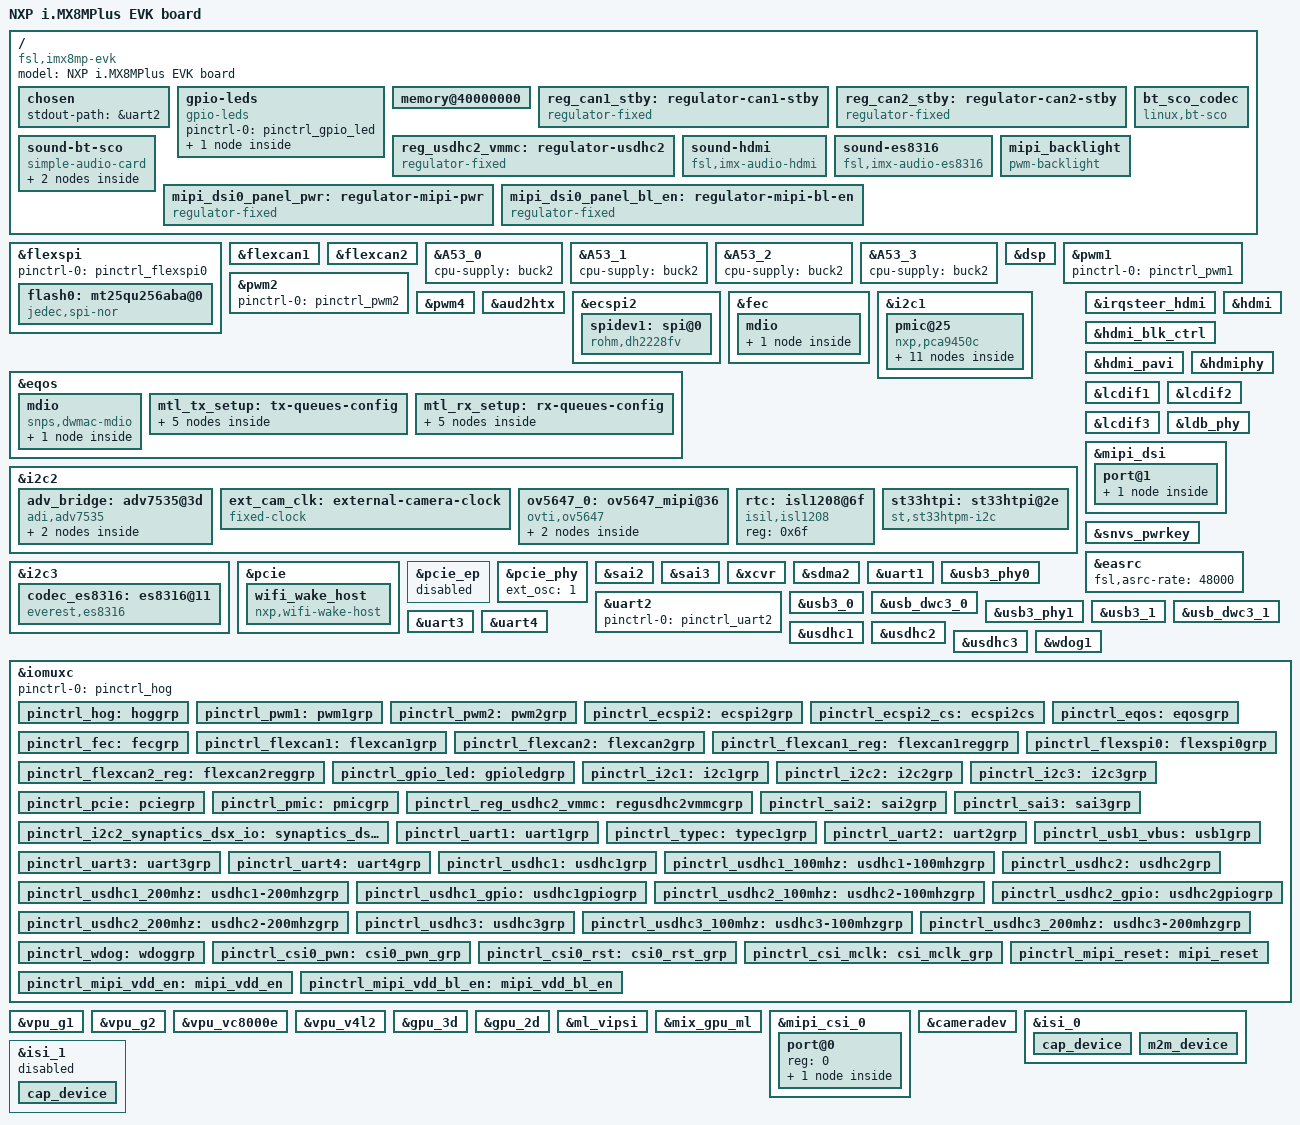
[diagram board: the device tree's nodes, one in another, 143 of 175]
// SPDX-License-Identifier: (GPL-2.0+ OR MIT)
/*
 * Copyright 2019 NXP
 */

/dts-v1/;

#include <dt-bindings/usb/pd.h>
#include "imx8mp.dtsi"

/ {
	model = "NXP i.MX8MPlus EVK board";
	compatible = "fsl,imx8mp-evk", "fsl,imx8mp";

	chosen {
		stdout-path = &uart2;
	};

	gpio-leds {
		compatible = "gpio-leds";
		pinctrl-names = "default";
		pinctrl-0 = <&pinctrl_gpio_led>;

		status {
			label = "yellow:status";
			gpios = <&gpio3 16 GPIO_ACTIVE_HIGH>;
			default-state = "on";
		};
	};

	memory@40000000 {
		device_type = "memory";
		reg = <0x0 0x40000000 0 0xc0000000>,
		      <0x1 0x00000000 0 0xc0000000>;
	};

	// mickey canbus test
	reg_can1_stby: regulator-can1-stby {
		compatible = "regulator-fixed";
		regulator-name = "can1-stby";
		pinctrl-names = "default";
		pinctrl-0 = <&pinctrl_flexcan1_reg>;
		regulator-min-microvolt = <3300000>;
		regulator-max-microvolt = <3300000>;
		gpio = <&gpio5 5 GPIO_ACTIVE_LOW>;
	};

	reg_can2_stby: regulator-can2-stby {
		compatible = "regulator-fixed";
		regulator-name = "can2-stby";
		pinctrl-names = "default";
		pinctrl-0 = <&pinctrl_flexcan2_reg>;
		regulator-min-microvolt = <3300000>;
		regulator-max-microvolt = <3300000>;
		gpio = <&gpio4 27 GPIO_ACTIVE_LOW>;
	};

	/* mickey org code
	reg_can1_stby: regulator-can1-stby {
		compatible = "regulator-fixed";
		regulator-name = "can1-stby";
		pinctrl-names = "default";
		pinctrl-0 = <&pinctrl_flexcan1_reg>;
		regulator-min-microvolt = <3300000>;
		regulator-max-microvolt = <3300000>;
		gpio = <&gpio5 5 GPIO_ACTIVE_HIGH>;
		enable-active-high;
	};

	reg_can2_stby: regulator-can2-stby {
		compatible = "regulator-fixed";
		regulator-name = "can2-stby";
		pinctrl-names = "default";
		pinctrl-0 = <&pinctrl_flexcan2_reg>;
		regulator-min-microvolt = <3300000>;
		regulator-max-microvolt = <3300000>;
		gpio = <&gpio4 27 GPIO_ACTIVE_HIGH>;
		enable-active-high;
	};
	*/
	
	// mickey, mmc0, remark by h/w design
	/*
	reg_usdhc1_vmmc: regulator-usdhc1 {
		compatible = "regulator-fixed";
		pinctrl-names = "default";
		//pinctrl-0 = <&pinctrl_reg_usdhc1_vmmc>;
		regulator-name = "VSD1_3V3";
		regulator-min-microvolt = <3300000>;
		regulator-max-microvolt = <3300000>;
		//gpio = <&gpio2 10 GPIO_ACTIVE_HIGH>;
		//enable-active-high;
	};
	*/
	
	reg_usdhc2_vmmc: regulator-usdhc2 {
		compatible = "regulator-fixed";
		pinctrl-names = "default";
		pinctrl-0 = <&pinctrl_reg_usdhc2_vmmc>;
		regulator-name = "VSD_3V3";
		regulator-min-microvolt = <3300000>;
		regulator-max-microvolt = <3300000>;
		gpio = <&gpio2 19 GPIO_ACTIVE_HIGH>;
		enable-active-high;
	};

	/* es8316 no need, so remark
	reg_audio_pwr: regulator-audio-pwr {
		compatible = "regulator-fixed";
		regulator-name = "audio-pwr";
		regulator-min-microvolt = <3300000>;
		regulator-max-microvolt = <3300000>;
		gpio = <&gpio4 29 GPIO_ACTIVE_HIGH>;
		enable-active-high;
		regulator-always-on;
	};
	*/

	bt_sco_codec: bt_sco_codec {
		#sound-dai-cells = <1>;
		compatible = "linux,bt-sco";
	};

	sound-bt-sco {
		compatible = "simple-audio-card";
		simple-audio-card,name = "bt-sco-audio";
		simple-audio-card,format = "dsp_a";
		simple-audio-card,bitclock-inversion;
		simple-audio-card,frame-master = <&btcpu>;
		simple-audio-card,bitclock-master = <&btcpu>;

		btcpu: simple-audio-card,cpu {
			sound-dai = <&sai2>;
			dai-tdm-slot-num = <2>;
			dai-tdm-slot-width = <16>;
		};

		/* mickey, org code */
		/*
		simple-audio-card,codec {
			sound-dai = <&bt_sco_codec 1>;
		};
		*/

		/* mickey */
		simple-audio-card,codec_es8316 {
			sound-dai = <&bt_sco_codec 1>;
		};
	};

	sound-hdmi {
		compatible = "fsl,imx-audio-hdmi";
		model = "audio-hdmi";
		audio-cpu = <&aud2htx>;
		hdmi-out;
		constraint-rate = <44100>,
				<88200>,
				<176400>,
				<32000>,
				<48000>,
				<96000>,
				<192000>;
		status = "okay";
	};

	/* mickey, org audio codec.
	sound-wm8960 {
		compatible = "fsl,imx-audio-wm8960";
		model = "wm8960-audio";
		audio-cpu = <&sai3>;
		audio-codec = <&codec>;
		audio-asrc = <&easrc>;
		hp-det-gpio = <&gpio4 28 0>;
		audio-routing =
			"Headphone Jack", "HP_L",
			"Headphone Jack", "HP_R",
			"Ext Spk", "SPK_LP",
			"Ext Spk", "SPK_LN",
			"Ext Spk", "SPK_RP",
			"Ext Spk", "SPK_RN",
			"LINPUT1", "Mic Jack",
			"LINPUT3", "Mic Jack",
			"Mic Jack", "MICB";
	};
	*/

	/* mickey, es8316 codec, audio-codec = <&codec>; */
    	sound-es8316 {
		compatible = "fsl,imx-audio-es8316";
		model = "imx-audio-es8316";
		audio-cpu = <&sai3>;
		audio-codec = <&codec_es8316>;
		//hp-det-gpio = <&gpio4 28 0>;
		simple-audio-card,format = "i2s";
		simple-audio-card,mclk-fs = <256>;
		simple-audio-card,widgets =
			"Microphone", "Mic Jack",
			"Headphone", "Headphone Jack";
		simple-audio-card,routing =
			"Mic Jack", "MICBIAS1",
			"IN1P", "Mic Jack",
		    	"Headphone Jack", "HPOL",
		    	"Headphone Jack", "HPOR";
		audio-routing = 
		    	"Headphone Jack", "HPOL",
		    	"Headphone Jack", "HPOR";
    	};

	/* mickey, remark due to not using
	sound-micfil {
		compatible = "fsl,imx-audio-card";
		model = "imx-audio-micfil";
		pri-dai-link {
			link-name = "micfil hifi";
			format = "i2s";
			cpu {
				sound-dai = <&micfil>;
			};
		};
	};
	*/

	/* mickey, remark due to not using
	sound-xcvr {
		compatible = "fsl,imx-audio-card";
		model = "imx-audio-xcvr";
		pri-dai-link {
			link-name = "XCVR PCM";
			cpu {
				sound-dai = <&xcvr>;
			};
		};
	};
	*/
	
	// mickey, auo lvds 21 inch, vdd en
	/* default using HDMI, so remark lvds
	lvds0_panel_pwr: regulator-lvds-pwr {
	    	compatible = "regulator-fixed";
    		regulator-name = "lvds-pwr";
    		pinctrl-0 = <&pinctrl_lvds_vdd_en>;
    		gpio = <&gpio1 10 GPIO_ACTIVE_HIGH>;
    		enable-active-high;
		regulator-boot-on;
		regulator-always-on;
	};
	
	// mickey, auo lvds 21 inch, bl en
	lvds0_panel_bl_en: regulator-lvds-bl-en {
	    	compatible = "regulator-fixed";
    		regulator-name = "lvds-bl-en";
    		pinctrl-0 = <&pinctrl_lvds_vdd_bl_en>;
    		gpio = <&gpio1 13 GPIO_ACTIVE_HIGH>;
    		enable-active-high;
		regulator-boot-on;
		regulator-always-on;
	};
	
	// mickey, auo lvds 21 inch
	lvds0_panel {
		compatible = "auo,t215hvn01";
		//compatible = "auo,m215htn01";
		regulator-name = "panel-simple";
		power-supply = <&lvds0_panel_pwr>;
		backlight = <&lvds_backlight>;
		
		data-mapping = "24";
		width-mm = <430>;
		height-mm = <270>;
		
		panel-timing {
			//clock-frequency = <72000000>; // typical value of 71.2 MHz
			clock-frequency = <148800000>;
			hactive = <1920>;
			vactive = <1080>;
			hsync-len = <44>;
			hback-porch = <88>;
			hfront-porch = <148>;
			vsync-len = <5>;
			vback-porch = <4>;
			vfront-porch = <36>;
			hsync-active = <0>;
			vsync-active = <0>;
		};

		port {
			panel_lvds0_in: endpoint {
				remote-endpoint = <&lvds0_out>;
			};
		};
	};

	lvds_backlight: lvds_backlight {
		compatible = "pwm-backlight";
		pwms = <&pwm2 0 100000>;
		status = "okay";
		power-supply = <&lvds0_panel_bl_en>;

		brightness-levels = < 0  1  2  3  4  5  6  7  8  9
				     10 11 12 13 14 15 16 17 18 19
				     20 21 22 23 24 25 26 27 28 29
				     30 31 32 33 34 35 36 37 38 39
				     40 41 42 43 44 45 46 47 48 49
				     50 51 52 53 54 55 56 57 58 59
				     60 61 62 63 64 65 66 67 68 69
				     70 71 72 73 74 75 76 77 78 79
				     80 81 82 83 84 85 86 87 88 89
				     90 91 92 93 94 95 96 97 98 99
				    100>;
		default-brightness-level = <80>;
	};
	*/

	/* mickey, remark due to not using
	cbtl04gp {
		compatible = "nxp,cbtl04gp";
		pinctrl-names = "default";
		pinctrl-0 = <&pinctrl_typec_mux>;
		switch-gpios = <&gpio4 20 GPIO_ACTIVE_LOW>;
		orientation-switch;

		port {
			usb3_data_ss: endpoint {
				remote-endpoint = <&typec_con_ss>;
			};
		};
	};
	*/
	
	// mickey, mipi dsi vcc en, gpio1 10
	mipi_dsi0_panel_pwr: regulator-mipi-pwr {
	    	compatible = "regulator-fixed";
    		regulator-name = "mipi-pwr";
    		pinctrl-0 = <&pinctrl_mipi_vdd_en>;
    		gpio = <&gpio1 10 GPIO_ACTIVE_HIGH>;
    		enable-active-high;
		//regulator-boot-on;
		//regulator-always-on;
	};
	
	// mickey, mipi dsi bl en, gpio1 9
	mipi_dsi0_panel_bl_en: regulator-mipi-bl-en {
	    	compatible = "regulator-fixed";
    		regulator-name = "mipi-bl-en";
    		pinctrl-0 = <&pinctrl_mipi_vdd_bl_en>;
    		gpio = <&gpio1 9 GPIO_ACTIVE_HIGH>;
    		enable-active-high;
		//regulator-boot-on;
		//regulator-always-on;
	};
	
	// mickey, mipi backlight
	mipi_backlight: mipi_backlight {
		compatible = "pwm-backlight";
		pwms = <&pwm1 0 100000>;
		power-supply = <&mipi_dsi0_panel_bl_en>;
		brightness-levels = < 
			0  1  2  3  4  5  6  7  8  9
			10 11 12 13 14 15 16 17 18 19
			20 21 22 23 24 25 26 27 28 29
			30 31 32 33 34 35 36 37 38 39
			40 41 42 43 44 45 46 47 48 49
			50 51 52 53 54 55 56 57 58 59
			60 61 62 63 64 65 66 67 68 69
			70 71 72 73 74 75 76 77 78 79
			80 81 82 83 84 85 86 87 88 89
			90 91 92 93 94 95 96 97 98 99
			100
		>;
		default-brightness-level = <100>;	
		status = "okay";
	};	
};

&flexspi {
	pinctrl-names = "default";
	pinctrl-0 = <&pinctrl_flexspi0>;
	status = "okay";

	flash0: mt25qu256aba@0 {
		reg = <0>;
		#address-cells = <1>;
		#size-cells = <1>;
		compatible = "jedec,spi-nor";
		spi-max-frequency = <80000000>;
		spi-tx-bus-width = <1>;
		spi-rx-bus-width = <4>;
	};
};

&flexcan1 {
	pinctrl-names = "default";
	pinctrl-0 = <&pinctrl_flexcan1>;
	xceiver-supply = <&reg_can1_stby>;
	status = "okay";
};

// mickey, remove pca6416, due to have no h/w s/w btn.
&flexcan2 {
	pinctrl-names = "default";
	pinctrl-0 = <&pinctrl_flexcan2>;
	xceiver-supply = <&reg_can2_stby>;
	//pinctrl-assert-gpios = <&pca6416 3 GPIO_ACTIVE_HIGH>;
	status = "okay";/* can2 pin conflict with pdm */
};

&A53_0 {
	cpu-supply = <&buck2>;
};

&A53_1 {
	cpu-supply = <&buck2>;
};

&A53_2 {
	cpu-supply = <&buck2>;
};

&A53_3 {
	cpu-supply = <&buck2>;
};

&dsp {
	status = "okay";
};

&pwm1 {
	pinctrl-names = "default";
	pinctrl-0 = <&pinctrl_pwm1>;
	status = "okay";
};

&pwm2 {
	pinctrl-names = "default";
	
	pinctrl-0 = <&pinctrl_pwm2>;
	status = "okay";
};

&pwm4 {
	pinctrl-names = "default";
	//pinctrl-0 = <&pinctrl_pwm4>; // mickey, remove
	status = "okay";
};

&aud2htx {
	status = "okay";
};

&ecspi2 {
	#address-cells = <1>;
	#size-cells = <0>;
	fsl,spi-num-chipselects = <1>;
	pinctrl-names = "default";
	pinctrl-0 = <&pinctrl_ecspi2 &pinctrl_ecspi2_cs>;
	cs-gpios = <&gpio5 13 GPIO_ACTIVE_LOW>;
	status = "okay";

	spidev1: spi@0 {
		reg = <0>;
		compatible = "rohm,dh2228fv";
		spi-max-frequency = <500000>;
	};
};

// mickey test 1G issue
&eqos {
	pinctrl-names = "default";
	pinctrl-0 = <&pinctrl_eqos>;
	phy-mode = "rgmii-id";
	phy-handle = <&ethphy0>;
	snps,force_thresh_dma_mode;
	snps,mtl-tx-config = <&mtl_tx_setup>;
	snps,mtl-rx-config = <&mtl_rx_setup>;
	status = "okay";

	// mickey test 1G
	/*
	fixed-link {
		speed = <1000>;
		full-duplex;
		pause;
	};
	*/

	mdio {
		compatible = "snps,dwmac-mdio";
		#address-cells = <1>;
		#size-cells = <0>;

		ethphy0: ethernet-phy@2 {
			compatible = "ethernet-phy-ieee802.3-c22";
			//compatible = "micrel,ksz9031";
			rxc-skew-ps = <1800>;
			rxdv-skew-ps = <0>;
			txc-skew-ps = <1800>;
			txen-skew-ps = <0>;
			reg = <2>;
			adi,rx-internal-delay-ps = <1800>; // mickey, test adin
		        adi,tx-internal-delay-ps = <2200>; // mickey, test adin
		        adi,fifo-depth-bits = <16>; // mickey, test adin
			eee-broken-1000t;
		};
	};

	mtl_tx_setup: tx-queues-config {
		snps,tx-queues-to-use = <5>;
		snps,tx-sched-sp;
		queue0 {
			snps,dcb-algorithm;
			snps,priority = <0x1>;
		};
		queue1 {
			snps,dcb-algorithm;
			snps,priority = <0x2>;
		};
		queue2 {
			snps,dcb-algorithm;
			snps,priority = <0x4>;
		};
		queue3 {
			snps,dcb-algorithm;
			snps,priority = <0x8>;
		};
		queue4 {
			snps,dcb-algorithm;
			snps,priority = <0xf0>;
		};
	};
	mtl_rx_setup: rx-queues-config {
		snps,rx-queues-to-use = <5>;
		snps,rx-sched-sp;
		queue0 {
			snps,dcb-algorithm;
			snps,priority = <0x1>;
			snps,map-to-dma-channel = <0>;
		};
		queue1 {
			snps,dcb-algorithm;
			snps,priority = <0x2>;
			snps,map-to-dma-channel = <1>;
		};
		queue2 {
			snps,dcb-algorithm;
			snps,priority = <0x4>;
			snps,map-to-dma-channel = <2>;
		};
		queue3 {
			snps,dcb-algorithm;
			snps,priority = <0x8>;
			snps,map-to-dma-channel = <3>;
		};
		queue4 {
			snps,dcb-algorithm;
			snps,priority = <0xf0>;
			snps,map-to-dma-channel = <4>;
		};
	};
};

&fec {
	pinctrl-names = "default";
	pinctrl-0 = <&pinctrl_fec>;
	phy-mode = "rgmii-id";
	phy-handle = <&ethphy1>;
	fsl,magic-packet;
	status = "okay";
	
	// mickey test 1G
	/*
	fixed-link {
		speed = <1000>;
		full-duplex;
		pause;
	};
	*/

	mdio {
		#address-cells = <1>;
		#size-cells = <0>;

		ethphy1: ethernet-phy@1 {
			compatible = "ethernet-phy-ieee802.3-c22";
			//compatible = "micrel,ksz9031";
			rxc-skew-ps = <1800>;
			rxdv-skew-ps = <0>;
			txc-skew-ps = <1800>;
			txen-skew-ps = <0>;
			reg = <1>;
			adi,rx-internal-delay-ps = <1800>; // mickey, test adin
		        adi,tx-internal-delay-ps = <2200>; // mickey, test adin
		        adi,fifo-depth-bits = <16>; // mickey, test adin
			eee-broken-1000t;
			// lan1 reset pin, gpio98
			//reset-gpios = <&gpio4 2 GPIO_ACTIVE_LOW>;
			reset-assert-us = <10000>;
			reset-deassert-us = <80000>;
		};
	};
};
// mickey test 1G issue

/* org code
&fec {
	pinctrl-names = "default";
	pinctrl-0 = <&pinctrl_fec>;
	phy-mode = "rgmii-id";
	phy-handle = <&ethphy1>;
	fsl,magic-packet;
	status = "okay";

	mdio {
		#address-cells = <1>;
		#size-cells = <0>;

		ethphy1: ethernet-phy@0 {
			compatible = "ethernet-phy-ieee802.3-c22";
			reg = <0>;
			reset-assert-us = <10000>;
			reset-deassert-us = <80000>;
		};
	};
};
*/

&i2c1 {
	clock-frequency = <400000>;
	pinctrl-names = "default";
	pinctrl-0 = <&pinctrl_i2c1>;
	status = "okay";

	pmic@25 {
		compatible = "nxp,pca9450c";
		reg = <0x25>;
		pinctrl-names = "default";
		pinctrl-0 = <&pinctrl_pmic>;
		interrupt-parent = <&gpio1>;
		interrupts = <3 IRQ_TYPE_LEVEL_LOW>;

		regulators {
			buck1: BUCK1 {
				regulator-name = "BUCK1";
				regulator-min-microvolt = <600000>;
				regulator-max-microvolt = <2187500>;
				regulator-boot-on;
				regulator-always-on;
				regulator-ramp-delay = <3125>;
			};

			buck2: BUCK2 {
				regulator-name = "BUCK2";
				regulator-min-microvolt = <600000>;
				regulator-max-microvolt = <2187500>;
				regulator-boot-on;
				regulator-always-on;
				regulator-ramp-delay = <3125>;
				nxp,dvs-run-voltage = <950000>;
				nxp,dvs-standby-voltage = <850000>;
			};

			buck4: BUCK4{
				regulator-name = "BUCK4";
				regulator-min-microvolt = <600000>;
				regulator-max-microvolt = <3400000>;
				regulator-boot-on;
				regulator-always-on;
			};

			buck5: BUCK5{
				regulator-name = "BUCK5";
				regulator-min-microvolt = <600000>;
				regulator-max-microvolt = <3400000>;
				regulator-boot-on;
				regulator-always-on;
			};

			buck6: BUCK6 {
				regulator-name = "BUCK6";
				regulator-min-microvolt = <600000>;
				regulator-max-microvolt = <3400000>;
				regulator-boot-on;
				regulator-always-on;
			};

			ldo1: LDO1 {
				regulator-name = "LDO1";
				regulator-min-microvolt = <1600000>;
				regulator-max-microvolt = <3300000>;
				regulator-boot-on;
				regulator-always-on;
			};

			ldo2: LDO2 {
				regulator-name = "LDO2";
				regulator-min-microvolt = <800000>;
				regulator-max-microvolt = <1150000>;
				regulator-boot-on;
				regulator-always-on;
			};

			ldo3: LDO3 {
				regulator-name = "LDO3";
				regulator-min-microvolt = <800000>;
				regulator-max-microvolt = <3300000>;
				regulator-boot-on;
				regulator-always-on;
			};

			ldo4: LDO4 {
				regulator-name = "LDO4";
				regulator-min-microvolt = <800000>;
				regulator-max-microvolt = <3300000>;
				regulator-boot-on;
				regulator-always-on;
			};

			ldo5: LDO5 {
				regulator-name = "LDO5";
				regulator-min-microvolt = <1800000>;
				regulator-max-microvolt = <3300000>;
				regulator-boot-on;
				regulator-always-on;
			};
		};
	};
};

&i2c2 {
	clock-frequency = <100000>;
	pinctrl-names = "default";
	pinctrl-0 = <&pinctrl_i2c2>;
	status = "okay";

	/* mickey, remove, due to not use */
	adv_bridge: adv7535@3d {
		compatible = "adi,adv7535";
		reg = <0x3d>;
		adi,addr-cec = <0x3b>;
		adi,dsi-lanes = <4>;
		status = "okay";

		port {
			adv7535_from_dsim: endpoint {
				remote-endpoint = <&dsim_to_adv7535>;
			};
		};
	};

	/* mickey, remove, due to not use
	lvds_bridge: lvds-to-hdmi-bridge@4c {
		compatible = "ite,it6263";
		reg = <0x4c>;
		reset-gpios = <&gpio1 10 GPIO_ACTIVE_LOW>;

		port {
			it6263_in: endpoint {
				remote-endpoint = <&lvds_out>;
			};
		};
	};
	*/

	/* org code
	ov5640_0: ov5640_mipi@3c {
		compatible = "ovti,ov5640";
		reg = <0x3c>;
		pinctrl-names = "default";
		pinctrl-0 = <&pinctrl_csi0_pwn>, <&pinctrl_csi0_rst>, <&pinctrl_csi_mclk>;
		clocks = <&clk IMX8MP_CLK_IPP_DO_CLKO2>;
		clock-names = "xclk";
		assigned-clocks = <&clk IMX8MP_CLK_IPP_DO_CLKO2>;
		assigned-clock-parents = <&clk IMX8MP_CLK_24M>;
		assigned-clock-rates = <24000000>;
		csi_id = <0>;
		powerdown-gpios = <&gpio2 11 GPIO_ACTIVE_HIGH>;
		reset-gpios = <&gpio1 6 GPIO_ACTIVE_LOW>;
		mclk = <24000000>;
		mclk_source = <0>;
		mipi_csi;
		status = "okay";

		port {
			ov5640_mipi_0_ep: endpoint {
				remote-endpoint = <&mipi_csi0_ep>;
				data-lanes = <1 2>;
				clock-lanes = <0>;
			};
		};
	};
	*/
	
	// mickey, test for ov5647
	ext_cam_clk: external-camera-clock {
	        compatible = "fixed-clock";
       	clock-frequency = <25000000>;
       	clock-output-names = "CLK_CAMERA_25MHZ";
       	#clock-cells = <0>;
    	}; 
	
	ov5647_0: ov5647_mipi@36 {
		compatible = "ovti,ov5647";
		reg = <0x36>;
		pinctrl-names = "default";
		pinctrl-0 = <&pinctrl_csi0_pwn>, <&pinctrl_csi0_rst>, <&pinctrl_csi_mclk>;
		clocks = <&ext_cam_clk>; 
		//clocks = <&clk IMX8MP_CLK_IPP_DO_CLKO2>;
		//clock-names = "xclk";
		//assigned-clocks = <&clk IMX8MP_CLK_IPP_DO_CLKO2>;
		//assigned-clock-parents = <&clk IMX8MP_CLK_24M>;
		//assigned-clock-rates = <24000000>;
		csi_id = <0>;
		powerdown-gpios = <&gpio3 23 GPIO_ACTIVE_LOW>;
		reset-gpios = <&gpio1 6 GPIO_ACTIVE_HIGH>;
		mclk = <24000000>;
		mclk_source = <0>;
		mipi_csi;
		status = "okay";

		port {
			ov5647_mipi_0_ep: endpoint {
				remote-endpoint = <&mipi_csi0_ep>;
				data-lanes = <1 2>;
				clock-lanes = <0>;
			};
		};
	};
	
	/* mickey, remove, due to not use
	ptn5110: tcpc@50 {
		compatible = "nxp,ptn5110";
		pinctrl-names = "default";
		pinctrl-0 = <&pinctrl_typec>;
		reg = <0x50>;
		interrupt-parent = <&gpio4>;
		interrupts = <19 8>;

		port {
			typec_dr_sw: endpoint {
				remote-endpoint = <&usb3_drd_sw>;
			};
		};

		usb_con: connector {
			compatible = "usb-c-connector";
			label = "USB-C";
			power-role = "dual";
			data-role = "dual";
			try-power-role = "sink";
			source-pdos = <PDO_FIXED(5000, 3000, PDO_FIXED_USB_COMM)>;
			sink-pdos = <PDO_FIXED(5000, 3000, PDO_FIXED_USB_COMM)
				     PDO_VAR(5000, 20000, 3000)>;
			op-sink-microwatt = <15000000>;
			self-powered;

			ports {
				#address-cells = <1>;
				#size-cells = <0>;

				port@1 {
					reg = <1>;
					typec_con_ss: endpoint {
						remote-endpoint = <&usb3_data_ss>;
					};
				};
			};
		};
	};
	*/

	// mickey, RTC
    	rtc: isl1208@6f {
        	compatible = "isil,isl1208";
        	reg = <0x6f>;
		status = "okay";
    	};

	// mickey, TPM
	st33htpi: st33htpi@2e {
        	compatible = "st,st33htpm-i2c";    	
        	reg = <0x2e>;
        	clock-frequency = <400000>;
        	//pinctrl-0 = <&pinctrl_tpm>;
      	};
};

&i2c3 {
	clock-frequency = <400000>;
	pinctrl-names = "default";
	pinctrl-0 = <&pinctrl_i2c3>;
	status = "okay";

	/* mickey, remove due to not using.
	pca6416: gpio@20 {
		compatible = "ti,tca6416";
		reg = <0x20>;
		gpio-controller;
		#gpio-cells = <2>;
	};
	*/

	/* mickey, org audio codec. 
	codec: wm8960@1a {
		compatible = "wlf,wm8960";
		reg = <0x1a>;
		clocks = <&audio_blk_ctrl IMX8MP_CLK_AUDIO_BLK_CTRL_SAI3_MCLK1>;
		clock-names = "mclk";
		wlf,shared-lrclk;
		wlf,hp-cfg = <3 2 3>;
		wlf,gpio-cfg = <1 3>;
		SPKVDD1-supply = <&reg_audio_pwr>;
	};
	*/

	// mickey, es8316 codec
	codec_es8316: es8316@11 {
		compatible = "everest,es8316";
		reg = <0x11>;
		clocks = <&audio_blk_ctrl IMX8MP_CLK_AUDIO_BLK_CTRL_SAI3_MCLK1>;
		clock-names = "mclk";
		wlf,shared-lrclk;
		wlf,hp-cfg = <3 2 3>;
		wlf,gpio-cfg = <1 3>;
		//SPKVDD1-supply = <&reg_audio_pwr>;
		#sound-dai-cells = <0>;
	};

	/*
	ov5640_1: ov5640_mipi@3c {
		compatible = "ovti,ov5640";
		reg = <0x3c>;
		pinctrl-names = "default";
		pinctrl-0 = <&pinctrl_csi0_pwn>, <&pinctrl_csi0_rst>, <&pinctrl_csi_mclk>;
		clocks = <&clk IMX8MP_CLK_IPP_DO_CLKO2>;
		clock-names = "xclk";
		assigned-clocks = <&clk IMX8MP_CLK_IPP_DO_CLKO2>;
		assigned-clock-parents = <&clk IMX8MP_CLK_24M>;
		assigned-clock-rates = <24000000>;
		csi_id = <0>;
		powerdown-gpios = <&gpio4 1 GPIO_ACTIVE_HIGH>;
		reset-gpios = <&gpio4 0 GPIO_ACTIVE_LOW>;
		mclk = <24000000>;
		mclk_source = <0>;
		mipi_csi;
		status = "disabled";

		port {
			ov5640_mipi_1_ep: endpoint {
				remote-endpoint = <&mipi_csi1_ep>;
				data-lanes = <1 2>;
				clock-lanes = <0>;
			};
		};
	};
	*/
};

&irqsteer_hdmi {
	status = "okay";
};

&hdmi_blk_ctrl {
	status = "okay";
};

&hdmi_pavi {
	status = "okay";
};

&hdmi {
	status = "okay";
};

&hdmiphy {
	status = "okay";
};

&lcdif1 {
	status = "okay";
};

&lcdif2 {
	status = "okay";
};

&lcdif3 {
	status = "okay";

	thres-low  = <1 2>;             /* (FIFO * 1 / 2) */
	thres-high = <3 4>;             /* (FIFO * 3 / 4) */
};

// mickey, auo lvds 21 inch
/* default using HDMI, so remark lvds
&ldb {
	status = "okay";
	fsl,dual-channel;

	lvds-channel@0 {
		//fsl,data-mapping = "jeida";
		fsl,data-mapping = "spwg";
		fsl,data-width = <24>;
		status = "okay";
		
		port@1 {
			reg = <1>;

			lvds0_out: endpoint {
				remote-endpoint = <&panel_lvds0_in>;
			};
		};
	};
};
*/
// mickey, auo lvds 21 inch

// mickey, org code
/*
&ldb {
	status = "okay";

	lvds-channel@0 {
		fsl,data-mapping = "jeida";
		fsl,data-width = <24>;
		status = "okay";

		port@1 {
			reg = <1>;

			lvds_out: endpoint {
				remote-endpoint = <&it6263_in>;
			};
		};
	};
};
*/

&ldb_phy {
	status = "okay";
};

// mickey, mipi_dsi ivo M101GWWC R5
/* remark dsi, due to verify the HDMI 
&mipi_dsi {
	status = "okay";
	panel@0 {
		compatible = "ivo,m101gwwc";
  		reg = <0>;
  		power-supply = <&mipi_dsi0_panel_pwr>;	
  		// for mipi reset
  		//pinctrl-0 = <&pinctrl_mipi_reset>;
		reset-gpio = <&gpio5 20 GPIO_ACTIVE_LOW>;
  		backlight = <&mipi_backlight>;
		panel-init-sequence = [
		       //page 0
			23 01 02 E0 00
			//password
			23 01 02 E1 93
			23 01 02 E2 65
			23 01 02 E3 F8
			//page1
			23 01 02 E0 01
			//set vcom
			23 01 02 00 01
			23 01 02 01 36
			
			//set vcom reverse
			23 01 02 03 01
			23 01 02 04 36
			
			23 01 02 12 A0
			
			//set gamma power,VGMP,VGMN,VGMN,VGSN
			23 01 02 17 00
			23 01 02 18 BF
			23 01 02 19 00
			23 01 02 1A 00
			23 01 02 1B BF
			23 01 02 1C 00
			
			//set gate power
			23 01 02 1F 6A
			23 01 02 20 28
			23 01 02 21 28
			23 01 02 22 7E
			//23 01 02 26 DE
			23 01 02 26 DF
			
			//set panel
			23 01 02 37 59
			23 01 02 38 05
			23 01 02 39 02
			23 01 02 3A 05
			23 01 02 3C 78
			23 01 02 3D FF
			23 01 02 3E FF
			23 01 02 3F FF
			
			//set TCON
			23 01 02 40 06
			23 01 02 41 A0
			23 01 02 43 14
			23 01 02 44 0E
			23 01 02 45 28
						
			//power voltage
			23 01 02 55 0F
			23 01 02 56 01
			23 01 02 57 69
			23 01 02 58 0A
			23 01 02 59 0A
			23 01 02 5A 2B
			23 01 02 5B 14
			
			//Gamma 2.2
			//23 01 02 5D 7E
			23 01 02 5D 7F
			23 01 02 5E 64
			23 01 02 5F 51
			23 01 02 60 3B
			23 01 02 61 34
			23 01 02 62 24
			23 01 02 63 29
			23 01 02 64 12
			23 01 02 65 2F
			23 01 02 66 30
			23 01 02 67 32
			23 01 02 68 4E
			23 01 02 69 3F
			23 01 02 6A 46
			23 01 02 6B 3D
			23 01 02 6C 39
			23 01 02 6D 2F
			23 01 02 6E 1D
			23 01 02 6F 12
			
			23 01 02 70 7F
			23 01 02 71 73
			23 01 02 72 60
			23 01 02 73 4F
			23 01 02 74 48
			23 01 02 75 3A
			23 01 02 76 3C
			23 01 02 77 27
			23 01 02 78 42
			23 01 02 79 42
			23 01 02 7A 45
			23 01 02 7B 65
			23 01 02 7C 56
			23 01 02 7D 61
			23 01 02 7E 51
			23 01 02 7F 51
			23 01 02 80 41
			23 01 02 81 33
			23 01 02 82 12
			
			//page 2 for GIP
			23 01 02 E0 02
			
			//GIP_L Pin mapping
			23 01 02 00 49
			23 01 02 01 48
			23 01 02 02 47
			23 01 02 03 46
			23 01 02 04 45
			23 01 02 05 44
			23 01 02 06 4A
			23 01 02 07 4B
			23 01 02 08 50
			23 01 02 09 1F
			23 01 02 0A 1F
			23 01 02 0B 1F
			23 01 02 0C 1F
			23 01 02 0D 1F
			23 01 02 0E 1F
			23 01 02 0F 51
			23 01 02 10 52
			23 01 02 11 53
			23 01 02 12 40
			23 01 02 13 41
			23 01 02 14 42
			23 01 02 15 43
			
			//GIP_R pin mapping
			23 01 02 16 49
			23 01 02 17 48
			23 01 02 18 47
			23 01 02 19 46
			23 01 02 1A 45
			23 01 02 1B 44
			23 01 02 1C 4A
			23 01 02 1D 4B
			23 01 02 1E 50
			23 01 02 1F 1F
			23 01 02 20 1F
			23 01 02 21 1F
			23 01 02 22 1F
			23 01 02 23 1F
			23 01 02 24 1F
			23 01 02 25 51
			23 01 02 26 52
			23 01 02 27 53
			23 01 02 28 40
			23 01 02 29 41
			23 01 02 2A 42
			23 01 02 2B 43
			
			//GIP_L_GS pin mapping
			23 01 02 2C 0A
			23 01 02 2D 0B
			23 01 02 2E 04
			23 01 02 2F 05
			23 01 02 30 06
			23 01 02 31 07
			23 01 02 32 09
			23 01 02 33 08
			23 01 02 34 03
			23 01 02 35 1F
			23 01 02 36 1F
			23 01 02 37 1F
			23 01 02 38 1F
			23 01 02 39 1F
			23 01 02 3A 1F
			23 01 02 3B 02
			23 01 02 3C 01
			23 01 02 3D 00
			23 01 02 3E 13
			23 01 02 3F 12
			23 01 02 40 11
			23 01 02 41 10
			
			//GIP_R_GS pin mapping
			23 01 02 42 0A
			23 01 02 43 0B
			23 01 02 44 04
			23 01 02 45 05
			23 01 02 46 06
			23 01 02 47 07
			23 01 02 48 09
			23 01 02 49 08
			23 01 02 4A 03
			23 01 02 4B 1F
			23 01 02 4C 1F
			23 01 02 4D 1F
			23 01 02 4E 1F
			23 01 02 4F 1F
			23 01 02 50 1F
			23 01 02 51 02
			23 01 02 52 01
			23 01 02 53 00
			23 01 02 54 13
			23 01 02 55 12
			23 01 02 56 11
			23 01 02 57 10
			
			//GIP Timing
			23 01 02 58 40
			23 01 02 59 00
			23 01 02 5A 00
			23 01 02 5B 30
			23 01 02 5C 07
			23 01 02 5D 40
			23 01 02 5E 01
			23 01 02 5F 02
			23 01 02 60 40
			23 01 02 61 01
			23 01 02 62 02
			23 01 02 63 70
			23 01 02 64 6B
			23 01 02 65 75
			23 01 02 66 0B
			23 01 02 67 74
			23 01 02 68 01
			23 01 02 69 64
			23 01 02 6A 65
			23 01 02 6B 00
			23 01 02 6C 00
			23 01 02 6D 04
			23 01 02 6E 04
			23 01 02 6F 89
			
			//GIPDR,VGHO_SEL,VGHO_SEL2,CKV_GROUP,CKV1_CON,CKV0_CON
			23 01 02 70 00
			23 01 02 71 00
			23 01 02 72 06
			23 01 02 73 7B
			23 01 02 74 00
			23 01 02 75 3C
			23 01 02 76 00
			23 01 02 77 0D
			23 01 02 78 2C
			23 01 02 79 00
			23 01 02 7A 00
			23 01 02 7B 00
			23 01 02 7C 00
			23 01 02 7D 03
			23 01 02 7E 7B
			
			//page 4
			23 01 02 E0 04
			23 01 02 09 14
			23 01 02 2B 2B
			23 01 02 2E 44
						
			//Add ESD Protect
			//page 0
			23 01 02 E0 00
			23 01 02 E6 02
			23 01 02 E7 0C
			
			//SLP OUT
			23 78 02 11 00
			23 05 02 29 00
			23 01 02 35 00
			
			//REGFLAG_END_OF_TABLE
			23 01 02 FF 00
				
			//05 78 01 11
			//05 1E 01 29		
		];

		panel-exit-sequence = [
			05 00 01 28
			05 00 01 10
		];
		
  		dsi-lanes = <4>;
  		video-mode = <2>;
		panel-width-mm = <134>;
		panel-height-mm = <214>;
				
		port {
			panel1_in: endpoint {
				remote-endpoint = <&mipi_dsi_bridge_out>;
			};
		};
	};
	
	port@2 {
		mipi_dsi_bridge_out: endpoint {
			remote-endpoint = <&panel1_in>;
		};
	};	
};
*/

&mipi_dsi {
	status = "okay";
	port@1 {
		dsim_to_adv7535: endpoint {
			remote-endpoint = <&adv7535_from_dsim>;
			attach-bridge;
		};
	};
};


&snvs_pwrkey {
	status = "okay";
};

&easrc {
	fsl,asrc-rate  = <48000>;
	status = "okay";
};

/* mickey, remove pdm
&micfil {
	#sound-dai-cells = <0>;
	pinctrl-names = "default";
	pinctrl-0 = <&pinctrl_pdm>;
	assigned-clocks = <&clk IMX8MP_CLK_PDM>;
	assigned-clock-parents = <&clk IMX8MP_AUDIO_PLL1_OUT>;
	assigned-clock-rates = <196608000>;
	status = "disabled";
};
*/

&pcie{
	pinctrl-names = "default";
	pinctrl-0 = <&pinctrl_pcie>;
	disable-gpio = <&gpio2 6 GPIO_ACTIVE_LOW>;
	reset-gpio = <&gpio2 7 GPIO_ACTIVE_LOW>;
	ext_osc = <1>;
	clocks = <&clk IMX8MP_CLK_HSIO_ROOT>,
		 <&clk IMX8MP_CLK_PCIE_AUX>,
		 <&clk IMX8MP_CLK_HSIO_AXI>,
		 <&clk IMX8MP_CLK_PCIE_ROOT>;
	clock-names = "pcie", "pcie_aux", "pcie_phy", "pcie_bus";
	assigned-clocks = <&clk IMX8MP_CLK_HSIO_AXI>,
			  <&clk IMX8MP_CLK_PCIE_AUX>;
	assigned-clock-rates = <500000000>, <10000000>;
	assigned-clock-parents = <&clk IMX8MP_SYS_PLL2_500M>,
				 <&clk IMX8MP_SYS_PLL2_50M>;
	l1ss-disabled;
	status = "okay";

	wifi_wake_host {
		compatible = "nxp,wifi-wake-host";
		interrupt-parent = <&gpio5>;
		interrupts = <21 IRQ_TYPE_LEVEL_LOW>;
		interrupt-names = "host-wake";
	};
};

&pcie_ep{
	pinctrl-names = "default";
	pinctrl-0 = <&pinctrl_pcie>;
	ext_osc = <1>;
	clocks = <&clk IMX8MP_CLK_HSIO_ROOT>,
		 <&clk IMX8MP_CLK_PCIE_AUX>,
		 <&clk IMX8MP_CLK_HSIO_AXI>,
		 <&clk IMX8MP_CLK_PCIE_ROOT>;
	clock-names = "pcie", "pcie_aux", "pcie_phy", "pcie_bus";
	assigned-clocks = <&clk IMX8MP_CLK_HSIO_AXI>,
			  <&clk IMX8MP_CLK_PCIE_AUX>;
	assigned-clock-rates = <500000000>, <10000000>;
	assigned-clock-parents = <&clk IMX8MP_SYS_PLL2_500M>,
				 <&clk IMX8MP_SYS_PLL2_50M>;
	status = "disabled";
};

&pcie_phy{
	ext_osc = <1>;
	status = "okay";
};

&sai2 {
	#sound-dai-cells = <0>;
	pinctrl-names = "default";
	pinctrl-0 = <&pinctrl_sai2>;
	assigned-clocks = <&clk IMX8MP_CLK_SAI2>;
	assigned-clock-parents = <&clk IMX8MP_AUDIO_PLL1_OUT>;
	assigned-clock-rates = <12288000>;
	status = "okay";
};

&sai3 {
	pinctrl-names = "default";
	pinctrl-0 = <&pinctrl_sai3>;
	assigned-clocks = <&clk IMX8MP_CLK_SAI3>;
	assigned-clock-parents = <&clk IMX8MP_AUDIO_PLL1_OUT>;
	assigned-clock-rates = <12288000>;
	clocks = <&audio_blk_ctrl IMX8MP_CLK_AUDIO_BLK_CTRL_SAI3_IPG>, <&clk IMX8MP_CLK_DUMMY>,
		 <&audio_blk_ctrl IMX8MP_CLK_AUDIO_BLK_CTRL_SAI3_MCLK1>, <&clk IMX8MP_CLK_DUMMY>,
		 <&clk IMX8MP_CLK_DUMMY>;
	clock-names = "bus", "mclk0", "mclk1", "mclk2", "mclk3";
	fsl,sai-mclk-direction-output;
	status = "okay";
};

&xcvr {
	#sound-dai-cells = <0>;
	status = "okay";
};

&sdma2 {
	status = "okay";
};

&uart1 { /* BT */
	pinctrl-names = "default";
	pinctrl-0 = <&pinctrl_uart1>;
	assigned-clocks = <&clk IMX8MP_CLK_UART1>;
	assigned-clock-parents = <&clk IMX8MP_SYS_PLL1_80M>;
	fsl,uart-has-rtscts;
	status = "okay";
};

&uart2 {
	/* console */
	pinctrl-names = "default";
	pinctrl-0 = <&pinctrl_uart2>;
	status = "okay";
};

&usb3_phy0 {
	//vbus-power-supply = <&ptn5110>;
	fsl,phy-tx-vref-tune = <0xe>;
	fsl,phy-tx-preemp-amp-tune = <3>;
	fsl,phy-tx-vboost-level = <5>;
	fsl,phy-comp-dis-tune = <7>;
	fsl,pcs-tx-deemph-3p5db = <0x21>;
	fsl,phy-pcs-tx-swing-full = <0x7f>;
	status = "okay";
};

&usb3_0 {
	status = "okay";
};

// mickey, dr_mode "otg" to "host" for upper side USB port(type A)
&usb_dwc3_0 {
	dr_mode = "host"; // host // otg // peripheral
	hnp-disable;
	srp-disable;
	adp-disable;
	usb-role-switch;
	role-switch-default-mode = "none";
	snps,dis-u1-entry-quirk;
	snps,dis-u2-entry-quirk;
	status = "okay";

	/* mickey, remark due to not use
	port {
		usb3_drd_sw: endpoint {
			remote-endpoint = <&typec_dr_sw>;
		};
	};
	*/
};

&usb3_phy1 {
	fsl,phy-tx-preemp-amp-tune = <3>;
	fsl,phy-tx-vref-tune = <0xb>;
	status = "okay";
};

&usb3_1 {
	status = "okay";
};

&usb_dwc3_1 {
	pinctrl-names = "default";
	pinctrl-0 = <&pinctrl_usb1_vbus>;
	dr_mode = "host";
	status = "okay";
};

// mickey, COM3
&uart3 {
	pinctrl-names = "default";
	pinctrl-0 = <&pinctrl_uart3>;
	assigned-clocks = <&clk IMX8MP_CLK_UART3>;
	assigned-clock-parents = <&clk IMX8MP_SYS_PLL1_80M>;
	//fsl,uart-has-rtscts;
	linux,rs485-enabled-at-boot-time;
	//rs485-rx-during-tx;
	//rs485-rts-active-low;
	//rs485-rts-delay = <0 0>;
	rs485-rts-active-high;
	rts-gpios = <&gpio5 9 GPIO_ACTIVE_HIGH>;
	status = "okay";
};

// mickey, COM4
&uart4 {
        pinctrl-names = "default";
        pinctrl-0 = <&pinctrl_uart4>;
        assigned-clocks = <&clk IMX8MP_CLK_UART4>;
        assigned-clock-parents = <&clk IMX8MP_SYS_PLL1_80M>;
        //fsl,uart-has-rtscts;
        linux,rs485-enabled-at-boot-time;
	//rs485-rx-during-tx;
	//rs485-rts-active-low;
	//rs485-rts-delay = <0 0>;
	rs485-rts-active-high;
	rts-gpios = <&gpio5 13 GPIO_ACTIVE_HIGH>;
        status = "okay";
};

// mickey, mmc0
&usdhc1 {
	assigned-clocks = <&clk IMX8MP_CLK_USDHC1>;
	assigned-clock-rates = <400000000>;
	pinctrl-names = "default", "state_100mhz", "state_200mhz";
	pinctrl-0 = <&pinctrl_usdhc1>, <&pinctrl_usdhc1_gpio>;
	pinctrl-1 = <&pinctrl_usdhc1_100mhz>, <&pinctrl_usdhc1_gpio>;
	pinctrl-2 = <&pinctrl_usdhc1_200mhz>, <&pinctrl_usdhc1_gpio>;
	cd-gpios = <&gpio2 10 GPIO_ACTIVE_LOW>;
	bus-width = <4>;
	status = "okay";
};

&usdhc2 {
	assigned-clocks = <&clk IMX8MP_CLK_USDHC2>;
	assigned-clock-rates = <400000000>;
	pinctrl-names = "default", "state_100mhz", "state_200mhz";
	pinctrl-0 = <&pinctrl_usdhc2>, <&pinctrl_usdhc2_gpio>;
	pinctrl-1 = <&pinctrl_usdhc2_100mhz>, <&pinctrl_usdhc2_gpio>;
	pinctrl-2 = <&pinctrl_usdhc2_200mhz>, <&pinctrl_usdhc2_gpio>;
	cd-gpios = <&gpio2 12 GPIO_ACTIVE_LOW>;
	vmmc-supply = <&reg_usdhc2_vmmc>;
	bus-width = <4>;
	status = "okay";
};

&usdhc3 {
	assigned-clocks = <&clk IMX8MP_CLK_USDHC3>;
	assigned-clock-rates = <400000000>;
	pinctrl-names = "default", "state_100mhz", "state_200mhz";
	pinctrl-0 = <&pinctrl_usdhc3>;
	pinctrl-1 = <&pinctrl_usdhc3_100mhz>;
	pinctrl-2 = <&pinctrl_usdhc3_200mhz>;
	bus-width = <8>;
	non-removable;
	status = "okay";
};

&wdog1 {
	pinctrl-names = "default";
	pinctrl-0 = <&pinctrl_wdog>;
	fsl,ext-reset-output;
	status = "okay";
};

&iomuxc {
	pinctrl-names = "default";
	pinctrl-0 = <&pinctrl_hog>;

	pinctrl_hog: hoggrp {
		fsl,pins = <
			MX8MP_IOMUXC_HDMI_DDC_SCL__HDMIMIX_HDMI_SCL	0x400001c3
			MX8MP_IOMUXC_HDMI_DDC_SDA__HDMIMIX_HDMI_SDA	0x400001c3
			MX8MP_IOMUXC_HDMI_HPD__HDMIMIX_HDMI_HPD		0x40000019
			MX8MP_IOMUXC_HDMI_CEC__HDMIMIX_HDMI_CEC		0x40000019
		>;
	};

	/* org code
	pinctrl_pwm1: pwm1grp {
		fsl,pins = <
			MX8MP_IOMUXC_GPIO1_IO01__PWM1_OUT	0x116
		>;
	};
	*/
	
	// mickey, pwm1
	pinctrl_pwm1: pwm1grp {
		fsl,pins = <
			MX8MP_IOMUXC_GPIO1_IO08__PWM1_OUT	0x116
		>;
	};

	pinctrl_pwm2: pwm2grp {
		fsl,pins = <
			MX8MP_IOMUXC_GPIO1_IO11__PWM2_OUT	0x116
		>;
	};

	/* mickey, remove
	pinctrl_pwm4: pwm4grp {
		fsl,pins = <
			MX8MP_IOMUXC_SAI5_RXFS__PWM4_OUT	0x116
		>;
	};
	*/

	pinctrl_ecspi2: ecspi2grp {
		fsl,pins = <
			MX8MP_IOMUXC_ECSPI2_SCLK__ECSPI2_SCLK		0x82
			MX8MP_IOMUXC_ECSPI2_MOSI__ECSPI2_MOSI		0x82
			MX8MP_IOMUXC_ECSPI2_MISO__ECSPI2_MISO		0x82
		>;
	};

	pinctrl_ecspi2_cs: ecspi2cs {
		fsl,pins = <
			MX8MP_IOMUXC_ECSPI2_SS0__GPIO5_IO13		0x40000
		>;
	};

	/* mickey, modify eqosgrp */
	pinctrl_eqos: eqosgrp {
		fsl,pins = <
			MX8MP_IOMUXC_ENET_MDC__ENET_QOS_MDC				0x3
			MX8MP_IOMUXC_ENET_MDIO__ENET_QOS_MDIO				0x3
			MX8MP_IOMUXC_ENET_RD0__ENET_QOS_RGMII_RD0			0x91
			MX8MP_IOMUXC_ENET_RD1__ENET_QOS_RGMII_RD1			0x91
			MX8MP_IOMUXC_ENET_RD2__ENET_QOS_RGMII_RD2			0x91
			MX8MP_IOMUXC_ENET_RD3__ENET_QOS_RGMII_RD3			0x91
			MX8MP_IOMUXC_ENET_RXC__CCM_ENET_QOS_CLOCK_GENERATE_RX_CLK	0x91
			MX8MP_IOMUXC_ENET_RX_CTL__ENET_QOS_RGMII_RX_CTL		0x91
			MX8MP_IOMUXC_ENET_TD0__ENET_QOS_RGMII_TD0			0x1f
			MX8MP_IOMUXC_ENET_TD1__ENET_QOS_RGMII_TD1			0x1f
			MX8MP_IOMUXC_ENET_TD2__ENET_QOS_RGMII_TD2			0x1f
			MX8MP_IOMUXC_ENET_TD3__ENET_QOS_RGMII_TD3			0x1f
			MX8MP_IOMUXC_ENET_TX_CTL__ENET_QOS_RGMII_TX_CTL		0x1f
			MX8MP_IOMUXC_ENET_TXC__CCM_ENET_QOS_CLOCK_GENERATE_TX_CLK	0x1f
			MX8MP_IOMUXC_SAI2_RXC__GPIO4_IO22				0x19
		>;
	};

	pinctrl_fec: fecgrp {
		fsl,pins = <
			MX8MP_IOMUXC_SAI1_RXD2__ENET1_MDC		0x3
			MX8MP_IOMUXC_SAI1_RXD3__ENET1_MDIO		0x3
			MX8MP_IOMUXC_SAI1_RXD4__ENET1_RGMII_RD0	0x91
			MX8MP_IOMUXC_SAI1_RXD5__ENET1_RGMII_RD1	0x91
			MX8MP_IOMUXC_SAI1_RXD6__ENET1_RGMII_RD2	0x91
			MX8MP_IOMUXC_SAI1_RXD7__ENET1_RGMII_RD3	0x91
			MX8MP_IOMUXC_SAI1_TXC__ENET1_RGMII_RXC		0x91
			MX8MP_IOMUXC_SAI1_TXFS__ENET1_RGMII_RX_CTL	0x91
			MX8MP_IOMUXC_SAI1_TXD0__ENET1_RGMII_TD0	0x1f
			MX8MP_IOMUXC_SAI1_TXD1__ENET1_RGMII_TD1	0x1f
			MX8MP_IOMUXC_SAI1_TXD2__ENET1_RGMII_TD2	0x1f
			MX8MP_IOMUXC_SAI1_TXD3__ENET1_RGMII_TD3	0x1f
			MX8MP_IOMUXC_SAI1_TXD4__ENET1_RGMII_TX_CTL	0x1f
			MX8MP_IOMUXC_SAI1_TXD5__ENET1_RGMII_TXC	0x1f
			MX8MP_IOMUXC_SAI1_RXD0__GPIO4_IO02		0x19
		>;
	};

	pinctrl_flexcan1: flexcan1grp {
		fsl,pins = <
			MX8MP_IOMUXC_SPDIF_RX__CAN1_RX          0x154
			MX8MP_IOMUXC_SPDIF_TX__CAN1_TX          0x154
		>;
	};

	pinctrl_flexcan2: flexcan2grp {
		fsl,pins = <
			MX8MP_IOMUXC_SAI5_MCLK__CAN2_RX         0x154
			MX8MP_IOMUXC_SAI5_RXD3__CAN2_TX         0x154
		>;
	};

	pinctrl_flexcan1_reg: flexcan1reggrp {
		fsl,pins = <
			MX8MP_IOMUXC_SPDIF_EXT_CLK__GPIO5_IO05  0x154   /* CAN1_STBY */
		>;
	};

	pinctrl_flexcan2_reg: flexcan2reggrp {
		fsl,pins = <
			MX8MP_IOMUXC_SAI2_MCLK__GPIO4_IO27      0x154   /* CAN2_STBY */
		>;
	};

	pinctrl_flexspi0: flexspi0grp {
		fsl,pins = <
			MX8MP_IOMUXC_NAND_ALE__FLEXSPI_A_SCLK           0x1c2
			MX8MP_IOMUXC_NAND_CE0_B__FLEXSPI_A_SS0_B        0x82
			MX8MP_IOMUXC_NAND_DATA00__FLEXSPI_A_DATA00      0x82
			MX8MP_IOMUXC_NAND_DATA01__FLEXSPI_A_DATA01      0x82
			MX8MP_IOMUXC_NAND_DATA02__FLEXSPI_A_DATA02      0x82
			MX8MP_IOMUXC_NAND_DATA03__FLEXSPI_A_DATA03      0x82
		>;
	};

	pinctrl_gpio_led: gpioledgrp {
		fsl,pins = <
			MX8MP_IOMUXC_NAND_READY_B__GPIO3_IO16	0x19
		>;
	};

	pinctrl_i2c1: i2c1grp {
		fsl,pins = <
			MX8MP_IOMUXC_I2C1_SCL__I2C1_SCL		0x400001c2
			MX8MP_IOMUXC_I2C1_SDA__I2C1_SDA		0x400001c2
		>;
	};

	pinctrl_i2c2: i2c2grp {
		fsl,pins = <
			MX8MP_IOMUXC_I2C2_SCL__I2C2_SCL		0x400001c2
			MX8MP_IOMUXC_I2C2_SDA__I2C2_SDA		0x400001c2
		>;
	};

	pinctrl_i2c3: i2c3grp {
		fsl,pins = <
			MX8MP_IOMUXC_I2C3_SCL__I2C3_SCL		0x400001c2
			MX8MP_IOMUXC_I2C3_SDA__I2C3_SDA		0x400001c2
		>;
	};

	/* org code
	pinctrl_mipi_dsi_en: mipi_dsi_en {
		fsl,pins = <
			MX8MP_IOMUXC_GPIO1_IO08__GPIO1_IO08	0x16
		>;
	};
	*/

	//MX8MP_IOMUXC_I2C4_SCL__PCIE_CLKREQ_B		0x61 /* open drain, pull up */
	pinctrl_pcie: pciegrp {
		fsl,pins = <			
			MX8MP_IOMUXC_SD1_DATA4__GPIO2_IO06		0x41
			MX8MP_IOMUXC_SD1_DATA5__GPIO2_IO07		0x41
			MX8MP_IOMUXC_I2C4_SDA__GPIO5_IO21		0x1c4
		>;
	};

	pinctrl_pmic: pmicgrp {
		fsl,pins = <
			MX8MP_IOMUXC_GPIO1_IO03__GPIO1_IO03	0x000001c0
		>;
	};
	
	// mickey, mmc0, remark by h/w design
	/*
	pinctrl_reg_usdhc1_vmmc: regusdhc1vmmc {
		fsl,pins = <
			MX8MP_IOMUXC_SD1_RESET_B__GPIO2_IO10	0x41
		>;
	};
	*/

	pinctrl_reg_usdhc2_vmmc: regusdhc2vmmcgrp {
		fsl,pins = <
			MX8MP_IOMUXC_SD2_RESET_B__GPIO2_IO19	0x41
		>;
	};

	/* mickey, remove pdm
	pinctrl_pdm: pdmgrp {
		fsl,pins = <
			MX8MP_IOMUXC_SAI5_RXC__AUDIOMIX_PDM_CLK		0xd6
			MX8MP_IOMUXC_SAI5_RXD0__AUDIOMIX_PDM_BIT_STREAM00	0xd6
			MX8MP_IOMUXC_SAI5_RXD1__AUDIOMIX_PDM_BIT_STREAM01	0xd6
			MX8MP_IOMUXC_SAI5_RXD2__AUDIOMIX_PDM_BIT_STREAM02	0xd6
			MX8MP_IOMUXC_SAI5_RXD3__AUDIOMIX_PDM_BIT_STREAM03	0xd6
		>;
	};
	*/

	pinctrl_sai2: sai2grp {
		fsl,pins = <
			MX8MP_IOMUXC_SAI2_TXC__AUDIOMIX_SAI2_TX_BCLK	0xd6
			MX8MP_IOMUXC_SAI2_TXFS__AUDIOMIX_SAI2_TX_SYNC	0xd6
			MX8MP_IOMUXC_SAI2_TXD0__AUDIOMIX_SAI2_TX_DATA00	0xd6
			MX8MP_IOMUXC_SAI2_RXD0__AUDIOMIX_SAI2_RX_DATA00	0xd6
		>;
	};

	/* mickey, org sai3grp
	pinctrl_sai3: sai3grp {
		fsl,pins = <
			MX8MP_IOMUXC_SAI3_TXFS__AUDIOMIX_SAI3_TX_SYNC	0xd6
			MX8MP_IOMUXC_SAI3_TXC__AUDIOMIX_SAI3_TX_BCLK	0xd6
			MX8MP_IOMUXC_SAI3_RXD__AUDIOMIX_SAI3_RX_DATA00	0xd6
			MX8MP_IOMUXC_SAI3_TXD__AUDIOMIX_SAI3_TX_DATA00	0xd6
			MX8MP_IOMUXC_SAI3_MCLK__AUDIOMIX_SAI3_MCLK	0xd6
			MX8MP_IOMUXC_SAI3_RXFS__GPIO4_IO28		0xd6
			MX8MP_IOMUXC_SAI3_RXC__GPIO4_IO29		0xd6
		>;
	};
	*/

	// mickey, es8316
	pinctrl_sai3: sai3grp {
		fsl,pins = <
			MX8MP_IOMUXC_SAI3_TXFS__AUDIOMIX_SAI3_TX_SYNC 0xd6 /* I2S0_LRCK */
			MX8MP_IOMUXC_SAI3_RXFS__AUDIOMIX_SAI3_RX_SYNC 0xd6 /* I2S0_LRCK */
			MX8MP_IOMUXC_SAI3_TXD__AUDIOMIX_SAI3_TX_DATA00 0xd6 /* I2S0_SDOUT */
			MX8MP_IOMUXC_SAI3_RXD__AUDIOMIX_SAI3_RX_DATA00 0xd6 /* I2S0_SDIN */
			MX8MP_IOMUXC_SAI3_TXC__AUDIOMIX_SAI3_TX_BCLK 0xd6 /* I2S0_CK */
			MX8MP_IOMUXC_SAI3_RXC__AUDIOMIX_SAI3_RX_BCLK 0xd6 /* I2S0_CK */
			MX8MP_IOMUXC_SAI3_MCLK__AUDIOMIX_SAI3_MCLK 0xd6 /* AUDIO MCLK */
			MX8MP_IOMUXC_SAI3_RXFS__GPIO4_IO28		0xd6
			MX8MP_IOMUXC_SAI3_RXC__GPIO4_IO29		0xd6
		>;
	};

	pinctrl_i2c2_synaptics_dsx_io: synaptics_dsx_iogrp {
		fsl,pins = <
			MX8MP_IOMUXC_GPIO1_IO09__GPIO1_IO09		0x16
		>;
	};

	pinctrl_uart1: uart1grp {
		fsl,pins = <
			MX8MP_IOMUXC_UART1_RXD__UART1_DCE_RX	0x140
			MX8MP_IOMUXC_UART1_TXD__UART1_DCE_TX	0x140
			MX8MP_IOMUXC_UART3_RXD__UART1_DCE_CTS	0x140
			MX8MP_IOMUXC_UART3_TXD__UART1_DCE_RTS	0x140
		>;
	};

	pinctrl_typec: typec1grp {
		fsl,pins = <
			MX8MP_IOMUXC_SAI1_TXD7__GPIO4_IO19	0x1c4
		>;
	};

	/* mickey, remove
	pinctrl_typec_mux: typec1muxgrp {
		fsl,pins = <
			MX8MP_IOMUXC_SAI1_MCLK__GPIO4_IO20	0x16
		>;
	};
	*/
	
	// mickey, tpm test
	//MX8MP_IOMUXC_SAI1_RXFS__GPIO4_IO00	0x19 /* Reset */
	//MX8MP_IOMUXC_SAI1_MCLK__GPIO4_IO20	0x16 /* IRQ */
	/*
	pinctrl_tpm: tpmgrp {
		fsl,pins = <
			MX8MP_IOMUXC_SAI1_MCLK__GPIO4_IO20	0x16
		>;
	};
	*/

	pinctrl_uart2: uart2grp {
		fsl,pins = <
			MX8MP_IOMUXC_UART2_RXD__UART2_DCE_RX	0x140
			MX8MP_IOMUXC_UART2_TXD__UART2_DCE_TX	0x140
		>;
	};

	pinctrl_usb1_vbus: usb1grp {
		fsl,pins = <
			MX8MP_IOMUXC_GPIO1_IO14__USB2_PWR		0x19
		>;
	};

	/* mickey, COM3 */
	pinctrl_uart3: uart3grp {
		fsl,pins = <
			MX8MP_IOMUXC_ECSPI1_SCLK__UART3_DCE_RX		0x140
			MX8MP_IOMUXC_ECSPI1_MOSI__UART3_DCE_TX		0x140
			MX8MP_IOMUXC_ECSPI1_SS0__UART3_DCE_RTS		0x140
			MX8MP_IOMUXC_ECSPI1_MISO__UART3_DCE_CTS		0x140
			MX8MP_IOMUXC_ECSPI1_SS0__GPIO5_IO09 		0x140
			MX8MP_IOMUXC_SAI5_RXFS__GPIO3_IO19	0x154
		>;
	};

	// mickey, COM4
	pinctrl_uart4: uart4grp {
		fsl,pins = <
			MX8MP_IOMUXC_ECSPI2_SCLK__UART4_DCE_RX		0x140
			MX8MP_IOMUXC_ECSPI2_MOSI__UART4_DCE_TX		0x140
			MX8MP_IOMUXC_ECSPI2_SS0__UART4_DCE_RTS		0x140
			MX8MP_IOMUXC_ECSPI2_MISO__UART4_DCE_CTS		0x140
			MX8MP_IOMUXC_ECSPI2_SS0__GPIO5_IO13		0x140
		>;
	};
	
	// mickey, mmc0
	pinctrl_usdhc1: usdhc1grp {
		fsl,pins = <
			MX8MP_IOMUXC_SD1_CLK__USDHC1_CLK	0x190
			MX8MP_IOMUXC_SD1_CMD__USDHC1_CMD	0x1d0
			MX8MP_IOMUXC_SD1_DATA0__USDHC1_DATA0	0x1d0
			MX8MP_IOMUXC_SD1_DATA1__USDHC1_DATA1	0x1d0
			MX8MP_IOMUXC_SD1_DATA2__USDHC1_DATA2	0x1d0
			MX8MP_IOMUXC_SD1_DATA3__USDHC1_DATA3	0x1d0
		>;
	};

	pinctrl_usdhc1_100mhz: usdhc1-100mhzgrp {
		fsl,pins = <
			MX8MP_IOMUXC_SD1_CLK__USDHC1_CLK	0x194
			MX8MP_IOMUXC_SD1_CMD__USDHC1_CMD	0x1d4
			MX8MP_IOMUXC_SD1_DATA0__USDHC1_DATA0	0x1d4
			MX8MP_IOMUXC_SD1_DATA1__USDHC1_DATA1	0x1d4
			MX8MP_IOMUXC_SD1_DATA2__USDHC1_DATA2	0x1d4
			MX8MP_IOMUXC_SD1_DATA3__USDHC1_DATA3	0x1d4
		>;
	};

	pinctrl_usdhc1_200mhz: usdhc1-200mhzgrp {
		fsl,pins = <
			MX8MP_IOMUXC_SD1_CLK__USDHC1_CLK	0x196
			MX8MP_IOMUXC_SD1_CMD__USDHC1_CMD	0x1d6
			MX8MP_IOMUXC_SD1_DATA0__USDHC1_DATA0	0x1d6
			MX8MP_IOMUXC_SD1_DATA1__USDHC1_DATA1	0x1d6
			MX8MP_IOMUXC_SD1_DATA2__USDHC1_DATA2	0x1d6
			MX8MP_IOMUXC_SD1_DATA3__USDHC1_DATA3	0x1d6
		>;
	};

	// mmc0 detect pin
	pinctrl_usdhc1_gpio: usdhc1gpiogrp {
		fsl,pins = <
			MX8MP_IOMUXC_SD1_RESET_B__GPIO2_IO10	0x1c4
		>;
	};
	// mickey, mmc0

	pinctrl_usdhc2: usdhc2grp {
		fsl,pins = <
			MX8MP_IOMUXC_SD2_CLK__USDHC2_CLK	0x190
			MX8MP_IOMUXC_SD2_CMD__USDHC2_CMD	0x1d0
			MX8MP_IOMUXC_SD2_DATA0__USDHC2_DATA0	0x1d0
			MX8MP_IOMUXC_SD2_DATA1__USDHC2_DATA1	0x1d0
			MX8MP_IOMUXC_SD2_DATA2__USDHC2_DATA2	0x1d0
			MX8MP_IOMUXC_SD2_DATA3__USDHC2_DATA3	0x1d0
			MX8MP_IOMUXC_GPIO1_IO04__USDHC2_VSELECT	0xc1
		>;
	};

	pinctrl_usdhc2_100mhz: usdhc2-100mhzgrp {
		fsl,pins = <
			MX8MP_IOMUXC_SD2_CLK__USDHC2_CLK	0x194
			MX8MP_IOMUXC_SD2_CMD__USDHC2_CMD	0x1d4
			MX8MP_IOMUXC_SD2_DATA0__USDHC2_DATA0	0x1d4
			MX8MP_IOMUXC_SD2_DATA1__USDHC2_DATA1	0x1d4
			MX8MP_IOMUXC_SD2_DATA2__USDHC2_DATA2	0x1d4
			MX8MP_IOMUXC_SD2_DATA3__USDHC2_DATA3	0x1d4
			MX8MP_IOMUXC_GPIO1_IO04__USDHC2_VSELECT 0xc1
		>;
	};

	pinctrl_usdhc2_200mhz: usdhc2-200mhzgrp {
		fsl,pins = <
			MX8MP_IOMUXC_SD2_CLK__USDHC2_CLK	0x196
			MX8MP_IOMUXC_SD2_CMD__USDHC2_CMD	0x1d6
			MX8MP_IOMUXC_SD2_DATA0__USDHC2_DATA0	0x1d6
			MX8MP_IOMUXC_SD2_DATA1__USDHC2_DATA1	0x1d6
			MX8MP_IOMUXC_SD2_DATA2__USDHC2_DATA2	0x1d6
			MX8MP_IOMUXC_SD2_DATA3__USDHC2_DATA3	0x1d6
			MX8MP_IOMUXC_GPIO1_IO04__USDHC2_VSELECT 0xc1
		>;
	};

	pinctrl_usdhc2_gpio: usdhc2gpiogrp {
		fsl,pins = <
			MX8MP_IOMUXC_SD2_CD_B__GPIO2_IO12	0x1c4
		>;
	};

	pinctrl_usdhc3: usdhc3grp {
		fsl,pins = <
			MX8MP_IOMUXC_NAND_WE_B__USDHC3_CLK	0x190
			MX8MP_IOMUXC_NAND_WP_B__USDHC3_CMD	0x1d0
			MX8MP_IOMUXC_NAND_DATA04__USDHC3_DATA0	0x1d0
			MX8MP_IOMUXC_NAND_DATA05__USDHC3_DATA1	0x1d0
			MX8MP_IOMUXC_NAND_DATA06__USDHC3_DATA2	0x1d0
			MX8MP_IOMUXC_NAND_DATA07__USDHC3_DATA3	0x1d0
			MX8MP_IOMUXC_NAND_RE_B__USDHC3_DATA4	0x1d0
			MX8MP_IOMUXC_NAND_CE2_B__USDHC3_DATA5	0x1d0
			MX8MP_IOMUXC_NAND_CE3_B__USDHC3_DATA6	0x1d0
			MX8MP_IOMUXC_NAND_CLE__USDHC3_DATA7	0x1d0
			MX8MP_IOMUXC_NAND_CE1_B__USDHC3_STROBE	0x190
		>;
	};

	pinctrl_usdhc3_100mhz: usdhc3-100mhzgrp {
		fsl,pins = <
			MX8MP_IOMUXC_NAND_WE_B__USDHC3_CLK	0x194
			MX8MP_IOMUXC_NAND_WP_B__USDHC3_CMD	0x1d4
			MX8MP_IOMUXC_NAND_DATA04__USDHC3_DATA0	0x1d4
			MX8MP_IOMUXC_NAND_DATA05__USDHC3_DATA1	0x1d4
			MX8MP_IOMUXC_NAND_DATA06__USDHC3_DATA2	0x1d4
			MX8MP_IOMUXC_NAND_DATA07__USDHC3_DATA3	0x1d4
			MX8MP_IOMUXC_NAND_RE_B__USDHC3_DATA4	0x1d4
			MX8MP_IOMUXC_NAND_CE2_B__USDHC3_DATA5	0x1d4
			MX8MP_IOMUXC_NAND_CE3_B__USDHC3_DATA6	0x1d4
			MX8MP_IOMUXC_NAND_CLE__USDHC3_DATA7	0x1d4
			MX8MP_IOMUXC_NAND_CE1_B__USDHC3_STROBE	0x194
		>;
	};

	pinctrl_usdhc3_200mhz: usdhc3-200mhzgrp {
		fsl,pins = <
			MX8MP_IOMUXC_NAND_WE_B__USDHC3_CLK	0x196
			MX8MP_IOMUXC_NAND_WP_B__USDHC3_CMD	0x1d6
			MX8MP_IOMUXC_NAND_DATA04__USDHC3_DATA0	0x1d6
			MX8MP_IOMUXC_NAND_DATA05__USDHC3_DATA1	0x1d6
			MX8MP_IOMUXC_NAND_DATA06__USDHC3_DATA2	0x1d6
			MX8MP_IOMUXC_NAND_DATA07__USDHC3_DATA3	0x1d6
			MX8MP_IOMUXC_NAND_RE_B__USDHC3_DATA4	0x1d6
			MX8MP_IOMUXC_NAND_CE2_B__USDHC3_DATA5	0x1d6
			MX8MP_IOMUXC_NAND_CE3_B__USDHC3_DATA6	0x1d6
			MX8MP_IOMUXC_NAND_CLE__USDHC3_DATA7	0x1d6
			MX8MP_IOMUXC_NAND_CE1_B__USDHC3_STROBE	0x196
		>;
	};

	pinctrl_wdog: wdoggrp {
		fsl,pins = <
			MX8MP_IOMUXC_GPIO1_IO02__WDOG1_WDOG_B	0x166
		>;
	};

	/* org code
	pinctrl_csi0_pwn: csi0_pwn_grp {
		fsl,pins = <
			MX8MP_IOMUXC_SD1_STROBE__GPIO2_IO11	0x19
		>;
	};
	*/
	
	// mickey, mipi csi pwndown
	pinctrl_csi0_pwn: csi0_pwn_grp {
		fsl,pins = <
			MX8MP_IOMUXC_SAI5_RXD2__GPIO3_IO23	0x19
		>;
	};
	
	pinctrl_csi0_rst: csi0_rst_grp {
		fsl,pins = <
			MX8MP_IOMUXC_GPIO1_IO06__GPIO1_IO06		0x19
		>;
	};

	pinctrl_csi_mclk: csi_mclk_grp {
		fsl,pins = <
			MX8MP_IOMUXC_GPIO1_IO15__CCM_CLKO2	0x59
		>;
	};
	
	// mickey, auo lvds 21 inch, gpio1 10 > panel vdd en
	/* default using HDMI, so remark lvds
	pinctrl_lvds_vdd_en: lvds_vdd_en {
		fsl,pins = <
			MX8MP_IOMUXC_GPIO1_IO10__GPIO1_IO10	0x19
		>;
	};
	
	// mickey, auo lvds 21 inch, gpio1 13 > lvds bl en
	pinctrl_lvds_vdd_bl_en: lvds_vdd_bl_en {
		fsl,pins = <
			MX8MP_IOMUXC_GPIO1_IO13__GPIO1_IO13	0x19
		>;
	};
	*/
	
	// mickey, mipi dsi vdd en, gpio1 10
	pinctrl_mipi_vdd_en: mipi_vdd_en {
		fsl,pins = <
			MX8MP_IOMUXC_GPIO1_IO10__GPIO1_IO10	0x19
		>;
	};
	
	// mickey, mipi dsi bl en, gpio1 9
	pinctrl_mipi_vdd_bl_en: mipi_vdd_bl_en {
		fsl,pins = <
			MX8MP_IOMUXC_GPIO1_IO09__GPIO1_IO09	0x19
		>;
	};
	
	// mickey, mipi_dsi for reset
	pinctrl_mipi_reset: mipi_reset {
		fsl,pins = <
			MX8MP_IOMUXC_I2C4_SCL__GPIO5_IO20	0x19
		>;
	};
};

&vpu_g1 {
	status = "okay";
};

&vpu_g2 {
	status = "okay";
};

&vpu_vc8000e {
	status = "okay";
};

&vpu_v4l2 {
	status = "okay";
};

&gpu_3d {
	status = "okay";
};

&gpu_2d {
	status = "okay";
};

&ml_vipsi {
	status = "okay";
};

&mix_gpu_ml {
	status = "okay";
};

&mipi_csi_0 {
	#address-cells = <1>;
	#size-cells = <0>;
	status = "okay";

	port@0 {
		reg = <0>;
		mipi_csi0_ep: endpoint {
			remote-endpoint = <&ov5647_mipi_0_ep>;
			data-lanes = <2>;
			csis-hs-settle = <13>;
			csis-clk-settle = <2>;
			csis-wclk;
		};
	};
};

/*
&mipi_csi_1 {
	#address-cells = <1>;
	#size-cells = <0>;
	status = "disabled";

	port@1 {
		reg = <1>;
		mipi_csi1_ep: endpoint {
			remote-endpoint = <&ov5640_mipi_1_ep>;
			data-lanes = <2>;
			csis-hs-settle = <13>;
			csis-clk-settle = <2>;
			csis-wclk;
		};
	};
};
*/

&cameradev {
	status = "okay";
};

&isi_0 {
	status = "okay";

	cap_device {
		status = "okay";
	};

	m2m_device {
		status = "okay";
	};
};

&isi_1 {
	status = "disabled";

	cap_device {
		status = "okay";
	};
};

